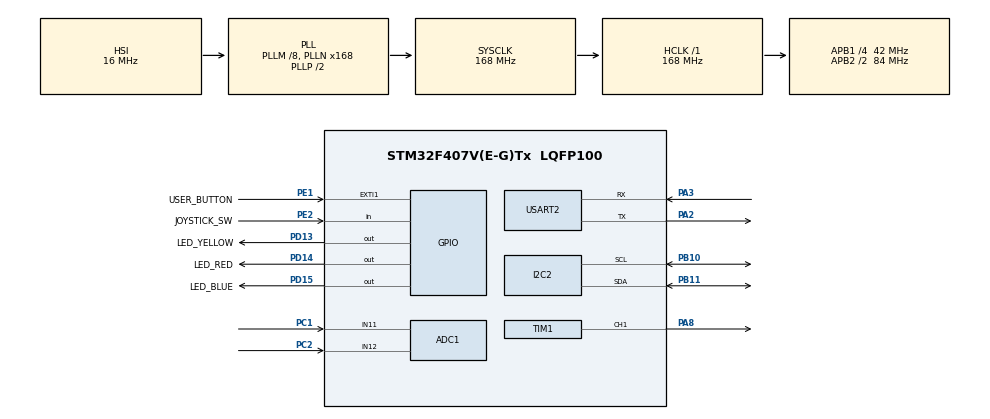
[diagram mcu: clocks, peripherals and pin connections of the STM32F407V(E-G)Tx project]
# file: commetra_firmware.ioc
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ADC1.Channel-0\#ChannelRegularConversion=ADC_CHANNEL_11
ADC1.Channel-1\#ChannelRegularConversion=ADC_CHANNEL_11
ADC1.NbrOfConversion=2
ADC1.NbrOfConversionFlag=1
ADC1.Rank-0\#ChannelRegularConversion=1
ADC1.Rank-1\#ChannelRegularConversion=2
ADC1.SamplingTime-0\#ChannelRegularConversion=ADC_SAMPLETIME_3CYCLES
ADC1.SamplingTime-1\#ChannelRegularConversion=ADC_SAMPLETIME_3CYCLES
ADC1.ScanConvMode=ENABLE
ADC1.master=1
FREERTOS.Tasks01=defaultTask,24,128,StartDefaultTask,Default,NULL,Dynamic,NULL,NULL
Mcu.Family=STM32F4
Mcu.Name=STM32F407V(E-G)Tx
Mcu.Package=LQFP100
NVIC.EXTI1_IRQn=true\:5\:0\:false\:false\:true\:true\:true\:true\:true
NVIC.PriorityGroup=NVIC_PRIORITYGROUP_4
NVIC.TIM6_DAC_IRQn=true\:15\:0\:false\:false\:true\:false\:false\:true\:true
NVIC.TimeBase=TIM6_DAC_IRQn
NVIC.TimeBaseIP=TIM6
NVIC.USART2_IRQn=true\:5\:0\:false\:false\:true\:true\:true\:true\:true
PA13.Mode=Serial_Wire
PA13.Signal=SYS_JTMS-SWDIO
PA14.Mode=Serial_Wire
PA14.Signal=SYS_JTCK-SWCLK
PA2.Mode=Asynchronous
PA2.Signal=USART2_TX
PA3.Mode=Asynchronous
PA3.Signal=USART2_RX
PA8.Signal=S_TIM1_CH1
PB10.Mode=I2C
PB10.Signal=I2C2_SCL
PB11.Mode=I2C
PB11.Signal=I2C2_SDA
PC1.Signal=ADCx_IN11
PC2.Signal=ADCx_IN12
PD13.GPIO_Label=LED_YELLOW
PD13.Signal=GPIO_Output
PD14.GPIO_Label=LED_RED
PD14.Signal=GPIO_Output
PD15.GPIO_Label=LED_BLUE
PD15.Signal=GPIO_Output
PE1.GPIO_Label=USER_BUTTON
PE1.Signal=GPXTI1
PE2.GPIO_Label=JOYSTICK_SW
PE2.Signal=GPIO_Input
PH0-OSC_IN.Mode=HSE-External-Oscillator
PH0-OSC_IN.Signal=RCC_OSC_IN
PH1-OSC_OUT.Mode=HSE-External-Oscillator
PH1-OSC_OUT.Signal=RCC_OSC_OUT
ProjectManager.HeapSize=0x200
ProjectManager.StackSize=0x400
ProjectManager.TargetToolchain=CMake
RCC.48MHZClocksFreq_Value=84000000
RCC.AHBFreq_Value=168000000
RCC.APB1CLKDivider=RCC_HCLK_DIV4
RCC.APB1Freq_Value=42000000
RCC.APB1TimFreq_Value=84000000
RCC.APB2CLKDivider=RCC_HCLK_DIV2
RCC.APB2Freq_Value=84000000
RCC.APB2TimFreq_Value=168000000
RCC.CortexFreq_Value=168000000
RCC.HCLKFreq_Value=168000000
RCC.HSE_VALUE=25000000
RCC.HSI_VALUE=16000000
RCC.LSE_VALUE=32768
RCC.PLLM=8
RCC.PLLN=168
RCC.SYSCLKFreq_VALUE=168000000
RCC.SYSCLKSource=RCC_SYSCLKSOURCE_PLLCLK
RCC.VCOOutputFreq_Value=336000000
SH.ADCx_IN11.0=ADC1_IN11,IN11
SH.ADCx_IN12.0=ADC1_IN12,IN12
SH.S_TIM1_CH1.0=TIM1_CH1,PWM Generation1 CH1
TIM1.Channel-PWM\ Generation1\ CH1=TIM_CHANNEL_1
TIM1.Prescaler=167
USART2.VirtualMode=VM_ASYNC
VP_FREERTOS_VS_CMSIS_V2.Mode=CMSIS_V2
VP_SYS_VS_tim6.Mode=TIM6
board=custom

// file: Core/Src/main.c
/* USER CODE BEGIN Header */
/**
  ******************************************************************************
  * @file           : main.c
  * @brief          : Main program body
  ******************************************************************************
  * @attention
  *
  * Copyright (c) 2026 STMicroelectronics.
  * All rights reserved.
  *
  * This software is licensed under terms that can be found in the LICENSE file
  * in the root directory of this software component.
  * If no LICENSE file comes with this software, it is provided AS-IS.
  *
  ******************************************************************************
  */
/* USER CODE END Header */
#include "main.h"
#include "cmsis_os.h"

/* USER CODE BEGIN Includes */
#include "heartbeat_task.h"
#include "button_task.h"
#include "uart_task.h"
/* USER CODE END Includes */

ADC_HandleTypeDef hadc1;

I2C_HandleTypeDef hi2c2;

TIM_HandleTypeDef htim1;

UART_HandleTypeDef huart2;

/* Definitions for defaultTask */
osThreadId_t defaultTaskHandle;
const osThreadAttr_t defaultTask_attributes = {
  .name = "defaultTask",
  .stack_size = 128 * 4,
  .priority = (osPriority_t) osPriorityNormal,
};

void SystemClock_Config(void);
static void MX_GPIO_Init(void);
static void MX_ADC1_Init(void);
static void MX_I2C2_Init(void);
static void MX_TIM1_Init(void);
static void MX_USART2_UART_Init(void);
void StartDefaultTask(void *argument);

int main(void)
{

  /* MCU Configuration--------------------------------------------------------*/

  /* Reset of all peripherals, Initializes the Flash interface and the Systick. */
  HAL_Init();

  /* Configure the system clock */
  SystemClock_Config();

  /* Initialize all configured peripherals */
  MX_GPIO_Init();
  MX_ADC1_Init();
  MX_I2C2_Init();
  MX_TIM1_Init();
  MX_USART2_UART_Init();

  /* Init scheduler */
  osKernelInitialize();

  /* Create the thread(s) */
  /* creation of defaultTask */
  defaultTaskHandle = osThreadNew(StartDefaultTask, NULL, &defaultTask_attributes);

  /* USER CODE BEGIN RTOS_THREADS */
  /* add threads, ... */
  HeartbeatTask_Create();
  ButtonTask_Create();
  UartTask_Create();
  /* USER CODE END RTOS_THREADS */

  /* Start scheduler */
  osKernelStart();

  /* We should never get here as control is now taken by the scheduler */

  /* Infinite loop */
  while (1)
  {

  }
}

void SystemClock_Config(void)
{
  RCC_OscInitTypeDef RCC_OscInitStruct = {0};
  RCC_ClkInitTypeDef RCC_ClkInitStruct = {0};

  /** Configure the main internal regulator output voltage
  */
  __HAL_RCC_PWR_CLK_ENABLE();
  __HAL_PWR_VOLTAGESCALING_CONFIG(PWR_REGULATOR_VOLTAGE_SCALE1);

  /** Initializes the RCC Oscillators according to the specified parameters
  * in the RCC_OscInitTypeDef structure.
  */
  RCC_OscInitStruct.OscillatorType = RCC_OSCILLATORTYPE_HSI;
  RCC_OscInitStruct.HSIState = RCC_HSI_ON;
  RCC_OscInitStruct.HSICalibrationValue = RCC_HSICALIBRATION_DEFAULT;
  RCC_OscInitStruct.PLL.PLLState = RCC_PLL_ON;
  RCC_OscInitStruct.PLL.PLLSource = RCC_PLLSOURCE_HSI;
  RCC_OscInitStruct.PLL.PLLM = 8;
  RCC_OscInitStruct.PLL.PLLN = 168;
  RCC_OscInitStruct.PLL.PLLP = RCC_PLLP_DIV2;
  RCC_OscInitStruct.PLL.PLLQ = 4;
  if (HAL_RCC_OscConfig(&RCC_OscInitStruct) != HAL_OK)
  {
    Error_Handler();
  }

  /** Initializes the CPU, AHB and APB buses clocks
  */
  RCC_ClkInitStruct.ClockType = RCC_CLOCKTYPE_HCLK|RCC_CLOCKTYPE_SYSCLK
                              |RCC_CLOCKTYPE_PCLK1|RCC_CLOCKTYPE_PCLK2;
  RCC_ClkInitStruct.SYSCLKSource = RCC_SYSCLKSOURCE_PLLCLK;
  RCC_ClkInitStruct.AHBCLKDivider = RCC_SYSCLK_DIV1;
  RCC_ClkInitStruct.APB1CLKDivider = RCC_HCLK_DIV4;
  RCC_ClkInitStruct.APB2CLKDivider = RCC_HCLK_DIV2;

  if (HAL_RCC_ClockConfig(&RCC_ClkInitStruct, FLASH_LATENCY_5) != HAL_OK)
  {
    Error_Handler();
  }
}

static void MX_ADC1_Init(void)
{

  ADC_ChannelConfTypeDef sConfig = {0};

  /** Configure the global features of the ADC (Clock, Resolution, Data Alignment and number of conversion)
  */
  hadc1.Instance = ADC1;
  hadc1.Init.ClockPrescaler = ADC_CLOCK_SYNC_PCLK_DIV4;
  hadc1.Init.Resolution = ADC_RESOLUTION_12B;
  hadc1.Init.ScanConvMode = ENABLE;
  hadc1.Init.ContinuousConvMode = DISABLE;
  hadc1.Init.DiscontinuousConvMode = DISABLE;
  hadc1.Init.ExternalTrigConvEdge = ADC_EXTERNALTRIGCONVEDGE_NONE;
  hadc1.Init.ExternalTrigConv = ADC_SOFTWARE_START;
  hadc1.Init.DataAlign = ADC_DATAALIGN_RIGHT;
  hadc1.Init.NbrOfConversion = 2;
  hadc1.Init.DMAContinuousRequests = DISABLE;
  hadc1.Init.EOCSelection = ADC_EOC_SINGLE_CONV;
  if (HAL_ADC_Init(&hadc1) != HAL_OK)
  {
    Error_Handler();
  }

  /** Configure for the selected ADC regular channel its corresponding rank in the sequencer and its sample time.
  */
  sConfig.Channel = ADC_CHANNEL_11;
  sConfig.Rank = 1;
  sConfig.SamplingTime = ADC_SAMPLETIME_3CYCLES;
  if (HAL_ADC_ConfigChannel(&hadc1, &sConfig) != HAL_OK)
  {
    Error_Handler();
  }

  /** Configure for the selected ADC regular channel its corresponding rank in the sequencer and its sample time.
  */
  sConfig.Rank = 2;
  if (HAL_ADC_ConfigChannel(&hadc1, &sConfig) != HAL_OK)
  {
    Error_Handler();
  }

}

static void MX_I2C2_Init(void)
{

  hi2c2.Instance = I2C2;
  hi2c2.Init.ClockSpeed = 100000;
  hi2c2.Init.DutyCycle = I2C_DUTYCYCLE_2;
  hi2c2.Init.OwnAddress1 = 0;
  hi2c2.Init.AddressingMode = I2C_ADDRESSINGMODE_7BIT;
  hi2c2.Init.DualAddressMode = I2C_DUALADDRESS_DISABLE;
  hi2c2.Init.OwnAddress2 = 0;
  hi2c2.Init.GeneralCallMode = I2C_GENERALCALL_DISABLE;
  hi2c2.Init.NoStretchMode = I2C_NOSTRETCH_DISABLE;
  if (HAL_I2C_Init(&hi2c2) != HAL_OK)
  {
    Error_Handler();
  }

}

static void MX_TIM1_Init(void)
{

  TIM_MasterConfigTypeDef sMasterConfig = {0};
  TIM_OC_InitTypeDef sConfigOC = {0};
  TIM_BreakDeadTimeConfigTypeDef sBreakDeadTimeConfig = {0};

  htim1.Instance = TIM1;
  htim1.Init.Prescaler = 167;
  htim1.Init.CounterMode = TIM_COUNTERMODE_UP;
  htim1.Init.Period = 65535;
  htim1.Init.ClockDivision = TIM_CLOCKDIVISION_DIV1;
  htim1.Init.RepetitionCounter = 0;
  htim1.Init.AutoReloadPreload = TIM_AUTORELOAD_PRELOAD_DISABLE;
  if (HAL_TIM_PWM_Init(&htim1) != HAL_OK)
  {
    Error_Handler();
  }
  sMasterConfig.MasterOutputTrigger = TIM_TRGO_RESET;
  sMasterConfig.MasterSlaveMode = TIM_MASTERSLAVEMODE_DISABLE;
  if (HAL_TIMEx_MasterConfigSynchronization(&htim1, &sMasterConfig) != HAL_OK)
  {
    Error_Handler();
  }
  sConfigOC.OCMode = TIM_OCMODE_PWM1;
  sConfigOC.Pulse = 0;
  sConfigOC.OCPolarity = TIM_OCPOLARITY_HIGH;
  sConfigOC.OCNPolarity = TIM_OCNPOLARITY_HIGH;
  sConfigOC.OCFastMode = TIM_OCFAST_DISABLE;
  sConfigOC.OCIdleState = TIM_OCIDLESTATE_RESET;
  sConfigOC.OCNIdleState = TIM_OCNIDLESTATE_RESET;
  if (HAL_TIM_PWM_ConfigChannel(&htim1, &sConfigOC, TIM_CHANNEL_1) != HAL_OK)
  {
    Error_Handler();
  }
  sBreakDeadTimeConfig.OffStateRunMode = TIM_OSSR_DISABLE;
  sBreakDeadTimeConfig.OffStateIDLEMode = TIM_OSSI_DISABLE;
  sBreakDeadTimeConfig.LockLevel = TIM_LOCKLEVEL_OFF;
  sBreakDeadTimeConfig.DeadTime = 0;
  sBreakDeadTimeConfig.BreakState = TIM_BREAK_DISABLE;
  sBreakDeadTimeConfig.BreakPolarity = TIM_BREAKPOLARITY_HIGH;
  sBreakDeadTimeConfig.AutomaticOutput = TIM_AUTOMATICOUTPUT_DISABLE;
  if (HAL_TIMEx_ConfigBreakDeadTime(&htim1, &sBreakDeadTimeConfig) != HAL_OK)
  {
    Error_Handler();
  }
  HAL_TIM_MspPostInit(&htim1);

}

static void MX_USART2_UART_Init(void)
{

  huart2.Instance = USART2;
  huart2.Init.BaudRate = 115200;
  huart2.Init.WordLength = UART_WORDLENGTH_8B;
  huart2.Init.StopBits = UART_STOPBITS_1;
  huart2.Init.Parity = UART_PARITY_NONE;
  huart2.Init.Mode = UART_MODE_TX_RX;
  huart2.Init.HwFlowCtl = UART_HWCONTROL_NONE;
  huart2.Init.OverSampling = UART_OVERSAMPLING_16;
  if (HAL_UART_Init(&huart2) != HAL_OK)
  {
    Error_Handler();
  }

}

static void MX_GPIO_Init(void)
{
  GPIO_InitTypeDef GPIO_InitStruct = {0};

  /* GPIO Ports Clock Enable */
  __HAL_RCC_GPIOE_CLK_ENABLE();
  __HAL_RCC_GPIOH_CLK_ENABLE();
  __HAL_RCC_GPIOC_CLK_ENABLE();
  __HAL_RCC_GPIOA_CLK_ENABLE();
  __HAL_RCC_GPIOB_CLK_ENABLE();
  __HAL_RCC_GPIOD_CLK_ENABLE();

  /*Configure GPIO pin Output Level */
  HAL_GPIO_WritePin(GPIOD, LED_YELLOW_Pin|LED_RED_Pin|LED_BLUE_Pin, GPIO_PIN_RESET);

  /*Configure GPIO pin : JOYSTICK_SW_Pin */
  GPIO_InitStruct.Pin = JOYSTICK_SW_Pin;
  GPIO_InitStruct.Mode = GPIO_MODE_INPUT;
  GPIO_InitStruct.Pull = GPIO_NOPULL;
  HAL_GPIO_Init(JOYSTICK_SW_GPIO_Port, &GPIO_InitStruct);

  /*Configure GPIO pins : LED_YELLOW_Pin LED_RED_Pin LED_BLUE_Pin */
  GPIO_InitStruct.Pin = LED_YELLOW_Pin|LED_RED_Pin|LED_BLUE_Pin;
  GPIO_InitStruct.Mode = GPIO_MODE_OUTPUT_PP;
  GPIO_InitStruct.Pull = GPIO_NOPULL;
  GPIO_InitStruct.Speed = GPIO_SPEED_FREQ_LOW;
  HAL_GPIO_Init(GPIOD, &GPIO_InitStruct);

  /*Configure GPIO pin : USER_BUTTON_Pin */
  GPIO_InitStruct.Pin = USER_BUTTON_Pin;
  GPIO_InitStruct.Mode = GPIO_MODE_IT_RISING;
  GPIO_InitStruct.Pull = GPIO_NOPULL;
  HAL_GPIO_Init(USER_BUTTON_GPIO_Port, &GPIO_InitStruct);

  /* EXTI interrupt init*/
  HAL_NVIC_SetPriority(EXTI1_IRQn, 5, 0);
  HAL_NVIC_EnableIRQ(EXTI1_IRQn);

}

/* USER CODE BEGIN 4 */
void HAL_GPIO_EXTI_Callback(uint16_t GPIO_Pin)
{
    if (GPIO_Pin == USER_BUTTON_Pin)
    {
        ButtonTask_Notify();
    }
}

/* USER CODE END 4 */

void StartDefaultTask(void *argument)
{
  for(;;)
  {
    osDelay(1);
  }
}

void HAL_TIM_PeriodElapsedCallback(TIM_HandleTypeDef *htim)
{
  if (htim->Instance == TIM6)
  {
    HAL_IncTick();
  }
}

void Error_Handler(void)
{
  __disable_irq();
  while (1)
  {
  }
}
